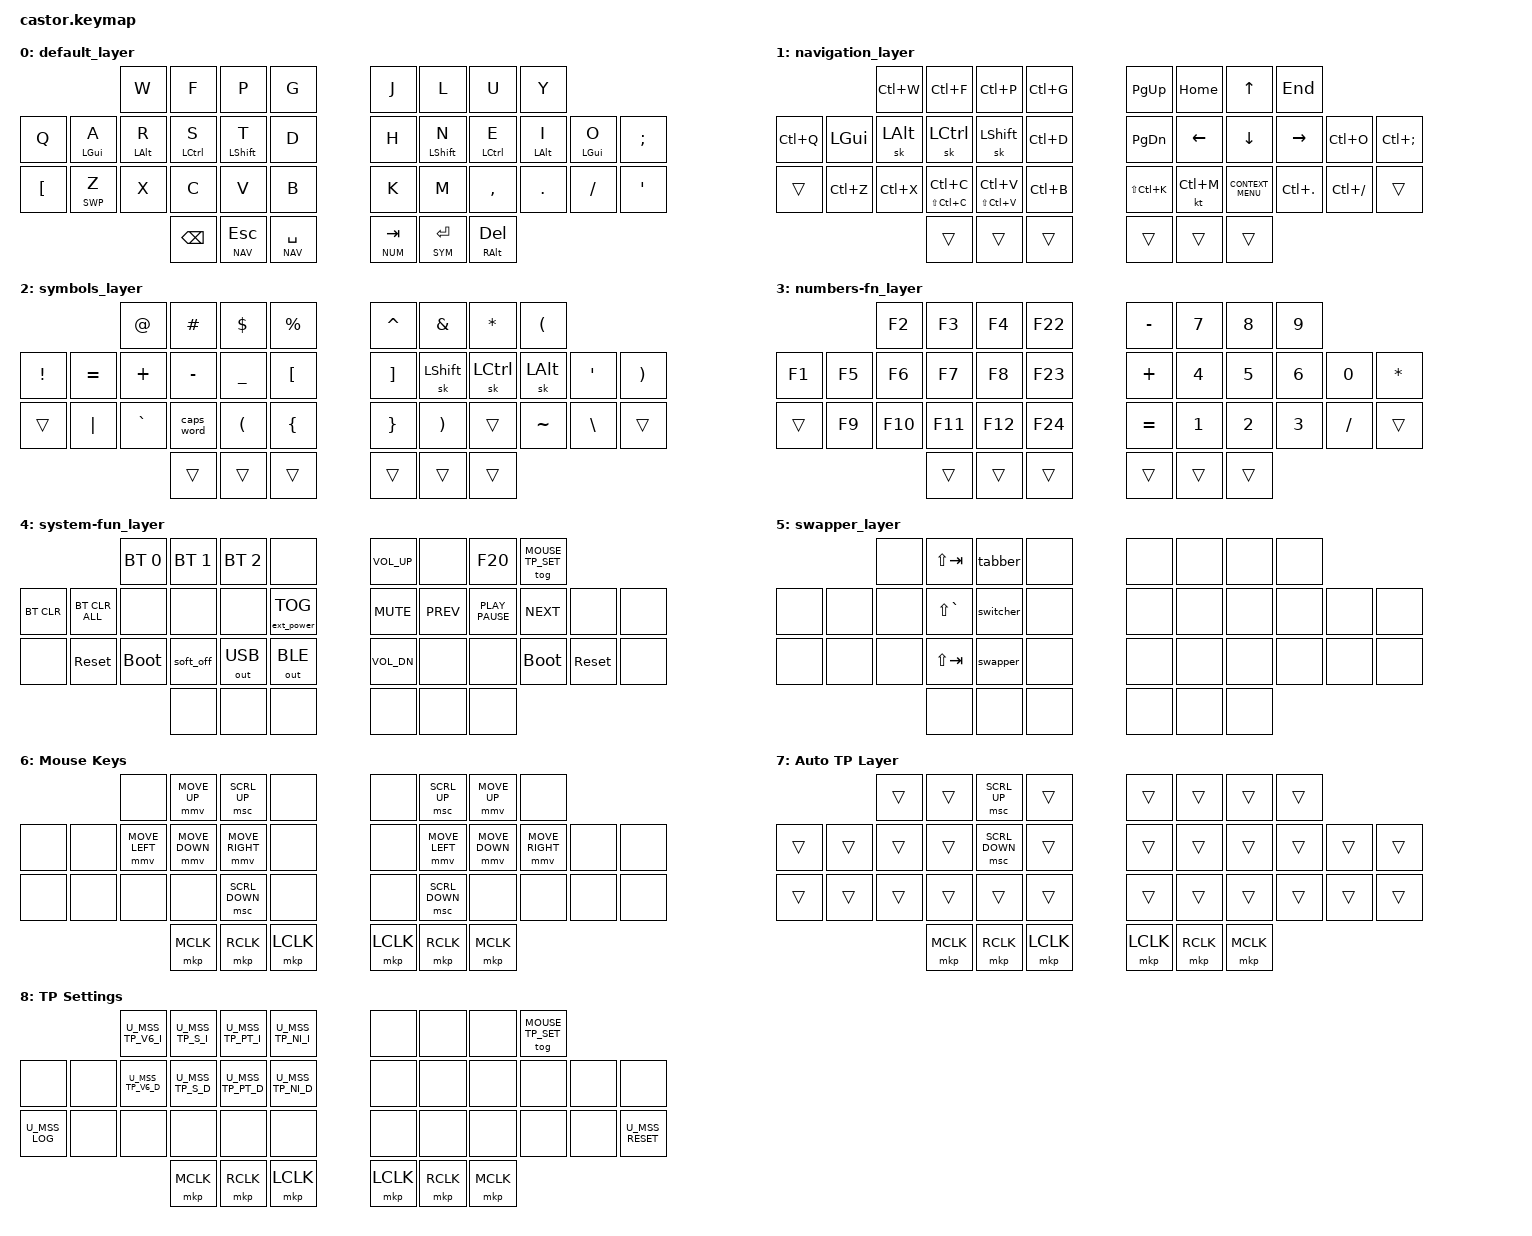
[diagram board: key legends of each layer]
#include <behaviors.dtsi>
#include <dt-bindings/zmk/bt.h>
#include <dt-bindings/zmk/keys.h>
#include <dt-bindings/zmk/outputs.h>
#include <dt-bindings/zmk/ext_power.h>

//        0  1  2  3       4  5  6  7
//  8  9 10 11 12 13      14 15 16 17 18 19
// 20 21 22 23 24 25      26 27 28 29 30 31
//          32 33 34      35 36 37
#define LEFT_KEYS 0 1 2 3 8 9 10 11 12 13 20 21 22 23 24 25
#define LEFT_THUMBS 32 33 34
#define RIGHT_KEYS 4 5 6 7 14 15 16 17 18 19 26 27 28 29 30 31
#define RIGHT_THUMBS 35 36 37

#define DEF 0
#define NAV 1
#define SYM 2
#define NUM 3
#define SYS 4
#define SWP 5
#define MOUSE_KEYS 6
#define MOUSE_TP 7
#define MOUSE_TP_SET 8

/*
* Defines to enable/disable features
*
* These defines allow us to conditionally enable and disable parts of the keymap config.
*
* For example, if we decide to build the firmware without the mouse features, we can
* disable all the config options that rely on those forks and modules without having
* to edit the entire keymap file manually every time.
*/

#define HAS_MOUSE_KEYS
#define HAS_MOUSE_TP

#ifdef HAS_MOUSE_KEYS
#include <dt-bindings/zmk/mouse.h>
#include <behaviors/mouse_keys.dtsi>
#endif  // HAS_MOUSE_KEYS

#ifdef HAS_MOUSE_TP
#include "include/mouse_listener_choice.dtsi"
#include "include/mouse_tp.dtsi"
#endif  // HAS_MOUSE_TP



// Adjust layer keys based on enabled features.
//
// This prevents build errors when we build the firmware
// without the mouse keys PR or the TP module.
#ifdef HAS_MOUSE_KEYS
#define U_THUMB_INNER &mo MOUSE_KEYS
#else
#define U_THUMB_INNER &none
#endif  // HAS_MOUSE_KEYS

#ifdef HAS_MOUSE_TP
#define U_TOG_TP_SET &tog MOUSE_TP_SET
#else
#define U_TOG_TP_SET &none
#endif  // HAS_MOUSE_TP

/ {
	conditional_layers {
		compatible = "zmk,conditional-layers";

		sys_layer {
			if-layers = <NAV SYM>;
			then-layer = <SYS>;
		};
		sys_layer2 {
			if-layers = <NAV NUM>;
			then-layer = <SYS>;
		};
	};
};

/ {
	combos {
		compatible = "zmk,combos";

		cmb_bspc {
			bindings = <&kp BACKSPACE>;
			key-positions = <0 1>;
		};
		cmb_del {
			bindings = <&kp DELETE>;
			key-positions = <1 2>;
		};
		cmb_undo {
			bindings = <&kp LC(Z)>;
			key-positions = <21 22>;
		};
		cmb_copy {
			bindings = <&kp LC(C)>;
			key-positions = <22 23>;
		};
		cmb_paste {
			bindings = <&kp LC(V)>;
			key-positions = <23 24>;
		};
		cmb_enter {
			bindings = <&kp ENTER>;
			key-positions = <24 25>;
		};
		cmb_caps {
			bindings = <&caps_word>;
			key-positions = <27 29>;
		};
		cmb_lang {
			bindings = <&kp SCROLLLOCK>;
			key-positions = <5 7>;
		};
		cmb_shcha {
			bindings = <&kp RA(U)>;
			key-positions = <6 7>;
		};
	};

	behaviors {
		ght: generic_hold_tap {
			compatible = "zmk,behavior-hold-tap";
			#binding-cells = <2>;
			flavor = "tap-preferred";
			tapping-term-ms = <200>;
			bindings = <&kp>, <&kp>;
		};

		// home row mods
		hml: home_row_mod_left {
			compatible = "zmk,behavior-hold-tap";
			label = "HRM Left";
			#binding-cells = <2>;
			flavor = "balanced";//produces a "hold" if another key is both pressed and released within the tapping-term.
			require-prior-idle-ms = <150>;// immediately resolves a HRM as "tap" when it is pressed shortly after another key has been tapped. As a rule of thumb, you want to set it to at least 10500/x where x is your (relaxed) WPM for English prose
			tapping-term-ms = <280>;//how long a key must be pressed to trigger the "hold" behavior
			quick-tap-ms = <175>;//If you press a tapped hold-tap again within quick-tap-ms milliseconds of the first press, it will always trigger the tap behavior.
			bindings = <&kp>, <&kp>;
			hold-trigger-key-positions = <RIGHT_KEYS RIGHT_THUMBS>;// List of keys on the right side of the keyboard
			hold-trigger-on-release;//delays the positional-hold-tap decision until the next key's release. With this, mods can be combined when held
		};
		hmr: home_row_mod_right {
			compatible = "zmk,behavior-hold-tap";
			label = "HRM Right";
			#binding-cells = <2>;
			flavor = "balanced";
			require-prior-idle-ms = <150>;
			tapping-term-ms = <280>;
			quick-tap-ms = <175>;
			bindings = <&kp>, <&kp>;
			hold-trigger-key-positions = <LEFT_KEYS LEFT_THUMBS>;// List of keys on the left side of the keyboard
			hold-trigger-on-release;
		};

		// one hand alt-tab / ctrl-tab
		tabber: tabber {
			compatible = "zmk,behavior-tri-state";
			label = "TABBER";
			#binding-cells = <0>;
			bindings = <&kt LCTRL>, <&kp TAB>, <&kt LCTRL>;
			ignored-key-positions = <1>; // shift-tab
		};
		switcher: switcher {
			compatible = "zmk,behavior-tri-state";
			label = "SWITCHER";
			#binding-cells = <0>;
			bindings = <&kt LALT>, <&kp GRAVE>, <&kt LALT>;
			ignored-key-positions = <11>; // shift-grave
		};
		swapper: swapper {
			compatible = "zmk,behavior-tri-state";
			label = "SWAPPER";
			#binding-cells = <0>;
			bindings = <&kt LALT>, <&kp TAB>, <&kt LALT>;
			ignored-key-positions = <23>; // shift-tab
		};

		//mouse scroll
		scroll_encoder: scroll_encoder {
			compatible = "zmk,behavior-sensor-rotate";
			#sensor-binding-cells = <0>;
			bindings = <&msc SCRL_UP>, <&msc SCRL_DOWN>;
			tap-ms = <30>;
    };
	};

	keymap {
		compatible = "zmk,keymap";
          default_layer { //0
          bindings = <
                              &kp W        &kp F            &kp P              &kp G             /* | */        &kp J          &kp L              &kp U            &kp Y
&kp Q          &hml LGUI A    &hml LALT R  &hml LCTRL S     &hml LSHIFT T      &kp D             /* | */        &kp H          &hmr LSHIFT N      &hmr LCTRL E     &hmr LALT I       &hmr LGUI O         &kp SEMI
&kp LBKT       &lt SWP Z      &kp X        &kp C            &kp V              &kp B             /* | */        &kp K          &kp M              &kp COMMA        &kp DOT           &kp SLASH           &kp SQT
                                          /* - - - - - - - - - - - - - - - - - - - - - - - - - - - - - - - - - - - - - - - - - - - - - - - - - - - - - */
                                           &kp BSPC         &lt NAV ESC 	     &lt NAV SPACE     /* | */        &lt NUM TAB    &lt SYM ENTER      &mt RALT DEL
            >;
            sensor-bindings = <&scroll_encoder>;
        };

          navigation_layer { //1
          bindings = <
                              &kp LC(W)     &kp LC(F)        &kp LC(P)          &kp LC(G)        /* | */        &kp PG_UP      &kp HOME           &kp UP          &kp END
&kp LC(Q)      &kp LGUI       &sk LALT      &sk LCTRL        &sk LSHIFT         &kp LC(D)        /* | */        &kp PG_DN      &kp LEFT           &kp DOWN        &kp RIGHT          &kp LC(O)         &kp LC(SEMI)
&trans         &kp LC(Z)      &kp LC(X)     &ght LS(LC(C)) LC(C) &ght LS(LC(V)) LC(V) &kp LC(B)  /* | */        &kp LS(LC(K))  &kt LC(M)          &kp K_CONTEXT_MENU &kp LC(PERIOD)  &kp LC(SLASH)     &trans
                                           /* - - - - - - - - - - - - - - - - - - - - - - - - - - - - - - - - - - - - - - - - - - - - - - - - - - - - - */
                                            &trans           &trans             &trans           /* | */        &trans         &trans             &trans
            >;
            sensor-bindings = <&scroll_encoder>;
        };

          symbols_layer { //2
          bindings = <
                            &kp AT          &kp HASH         &kp DOLLAR         &kp PERCENT      /* | */        &kp CARET      &kp AMPERSAND      &kp STAR          &kp LPAR
&kp EXCL      &kp EQUAL     &kp PLUS        &kp MINUS        &kp UNDER          &kp LBKT         /* | */        &kp RBKT       &sk LSHIFT         &sk LCTRL         &sk LALT          &kp SQT            &kp RPAR
&trans        &kp PIPE      &kp GRAVE       &caps_word       &kp LPAR           &kp LBRC         /* | */        &kp RBRC       &kp RPAR           &trans            &kp TILDE         &kp BACKSLASH      &trans
                                            /* - - - - - - - - - - - - - - -  - - - - - - - - - - - - - - - - - - - - - - - - - - - - - - - - - - - - - */
                                            &trans           &trans             &trans           /* | */        &trans         &trans             &trans
            >;
            sensor-bindings = <&scroll_encoder>;
        };

          numbers-fn_layer { //3
          bindings = <
                            &kp F2          &kp F3          &kp F4              &kp F22          /* | */        &kp MINUS      &kp N7            &kp N8            &kp N9
&kp F1        &kp F5        &kp F6          &kp F7          &kp F8              &kp F23          /* | */        &kp PLUS       &kp N4            &kp N5            &kp N6            &kp N0              &kp STAR
&trans        &kp F9        &kp F10         &kp F11         &kp F12             &kp F24          /* | */        &kp EQUAL      &kp N1            &kp N2            &kp N3            &kp SLASH           &trans
                                            /* - - - - - - - - - - - - - - - - - - - - - - - - - - - - - - - - - - - - - - - - - - - - - - - - - - - - */
                                            &trans           &trans             &trans           /* | */        &trans         &trans            &trans
            >;
            sensor-bindings = <&scroll_encoder>;
        };

          system-fun_layer { //4
          bindings = <
                               &bt BT_SEL 0  &bt BT_SEL 1  &bt BT_SEL 2    &none                 /* | */        &kp K_VOL_UP    &none             &kp F20 /* mic */  U_TOG_TP_SET
&bt BT_CLR    &bt BT_CLR_ALL   &none         &none         &none           &ext_power EP_TOG     /* | */        &kp K_MUTE      &kp K_PREV        &kp K_PLAY_PAUSE   &kp K_NEXT       &none              &none
&none         &sys_reset       &bootloader   &soft_off     &out OUT_USB    &out OUT_BLE          /* | */        &kp K_VOL_DN    &none             &none              &bootloader      &sys_reset         &none
                                            /* - - - - - - - - - - - - - - - - - - - - - - - - - - - - - - - - - - - - - - - - - - - - - - - - - - - - - */
                                             &none         &none           &none                 /* | */        &none           &none             &none
            >;
            sensor-bindings = <&inc_dec_kp C_VOLUME_UP C_VOL_DN>;
        };

					swapper_layer { //5
					bindings = <
			        							&none         &kp LS(TAB)     &tabber         &none                  /* | */        &none            &none          	&none  			      &none
&none         &none         &none         &kp LS(GRAVE)   &switcher       &none                  /* | */        &none            &none          	&none  			      &none             &none         &none
&none         &none         &none         &kp LS(TAB)     &swapper        &none                  /* | */        &none            &none          	&none  			      &none             &none         &none
                                          /* - - - - - - - - - - - - - - - - - - - - - - - - - - - - - - - - - - - - - - - - - - - - - - - - - - - - - - */
                                          &none           &none           &none                  /* | */        &none            &none            &none
			>;
		};

#ifdef HAS_MOUSE_KEYS

		mouse_keys {  //6
			display-name = "Mouse Keys";
			bindings = <
														&none          &mmv MOVE_UP    &msc SCRL_UP    &none                 /* | */        &none            &msc SCRL_UP     &mmv MOVE_UP      &none
&none         &none         &mmv MOVE_LEFT &mmv MOVE_DOWN  &mmv MOVE_RIGHT &none                 /* | */        &none            &mmv MOVE_LEFT   &mmv MOVE_DOWN    &mmv MOVE_RIGHT   &none        &none
&none         &none         &none          &none           &msc SCRL_DOWN  &none                 /* | */        &none            &msc SCRL_DOWN   &none             &none             &none        &none
                                           /* - - - - - - - - - - - - - - - - - - - - - - - - - - - - - - - - - - - - - - - - - - - - - - - - - - - - - */
                                           &mkp MCLK       &mkp RCLK       &mkp LCLK             /* | */        &mkp LCLK        &mkp RCLK        &mkp MCLK
			>;
		};

#endif

#ifdef HAS_MOUSE_TP

		// Automatically activated when the mouse or trackpoint moves.
		// Configured in `include/mouse_tp.dtsi`.
					auto_tp_layer { //7
					display-name = "Auto TP Layer";
					bindings = <
			        							&trans        &trans          &msc SCRL_UP    &trans                 /* | */        &trans           &trans         	&trans 			      &trans
&trans        &trans        &trans        &trans          &msc SCRL_DOWN  &trans                 /* | */        &trans           &trans         	&trans 			      &trans            &trans        &trans
&trans        &trans        &trans        &trans          &trans          &trans                 /* | */        &trans           &trans         	&trans 			      &trans            &trans        &trans
                                          /* - - - - - - - - - - - - - - - - - - - - - - - - - - - - - - - - - - - - - - - - - - - - - - - - - - - - - - */
                                          &mkp MCLK       &mkp RCLK       &mkp LCLK              /* | */        &mkp LCLK        &mkp RCLK        &mkp MCLK
			>;
		};

		// You can find the defines for the actual key press behaviors in `include/mouse_tp.dtsi`.
					trackpoint_settings { //8
					display-name = "TP Settings";
					bindings = <  /*  max speed     sensitivity     tap sensitivity  negative inertia      */
			                      U_MSS_TP_V6_I	U_MSS_TP_S_I    U_MSS_TP_PT_I    U_MSS_TP_NI_I	       /* | */        &none            &none            &none             U_TOG_TP_SET
&none         &none         U_MSS_TP_V6_D U_MSS_TP_S_D    U_MSS_TP_PT_D    U_MSS_TP_NI_D	       /* | */        &none            &none            &none             &none             &none       &none
U_MSS_LOG     &none         &none         &none           &none            &none                 /* | */        &none            &none            &none             &none             &none       U_MSS_RESET
                                          /* - - - - - - - - - - - - - - - - - - - - - - - - - - - - - - - - - - - - - - - - - - - - - - - - - - - - - - */
                                          &mkp MCLK       &mkp RCLK       &mkp LCLK              /* | */        &mkp LCLK        &mkp RCLK        &mkp MCLK
			>;
		};

#endif
	};

};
